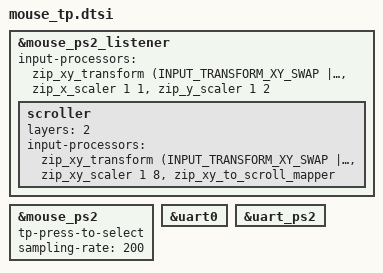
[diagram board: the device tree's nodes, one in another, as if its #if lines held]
#ifdef HAS_MOUSE_TP
  #include <dt-bindings/zmk/mouse.h>
  #include <dt-bindings/zmk/mouse_settings.h>
  #include <dt-bindings/zmk/input_transform.h>
  #include <input/processors.dtsi>
  #include <behaviors/mouse_keys.dtsi>
  #include <behaviors/mouse_setting.dtsi>

 /*
  * Key Behaviors to adjust settings
  */

  // They key codes below can be used to adjust the TP settings at runtime
  // without needing to recompile the firmware.
  //
  // The values will be logged and saved in the config on the controller flash
  // after 60s (CONFIG_ZMK_SETTINGS_SAVE_DEBOUNCE).
  //
  // On boot the settings will be restored again.
  //
  // If you prefer a more explicit way of configuration, you can also hardcode
  // these settings in `&mouse_ps2`.
  //
  // If you set these settings in `&mouse_ps2`, you will still be able to
  // adjust the values during runtime with these key codes, but after
  // restarting the board the values in `&mouse_ps2` will be restored and not
  // the ones stored in the flash using the key codes.


  // How sensitive the trackpoint is
  #define U_MSS_TP_S_I &mms MS_TP_SENSITIVITY_INCR
  #define U_MSS_TP_S_D &mms MS_TP_SENSITIVITY_DECR


  // The maximum speed the trackpoint will accelerate to
  #define U_MSS_TP_V6_I &mms MS_TP_VALUE6_INCR
  #define U_MSS_TP_V6_D &mms MS_TP_VALUE6_DECR


  // I am not quite sure tbh... default seems fine.
  #define U_MSS_TP_NI_I &mms MS_TP_NEG_INERTIA_INCR
  #define U_MSS_TP_NI_D &mms MS_TP_NEG_INERTIA_DECR


  // How hard you have to press to activate the "Press To Select" feature that
  // lets you tap or press on the trackpoint to click.
  //
  // Not all trackpoints support it and you have to enable
  // `tp-press-to-select;` in `&mouse_ps2` first.
  #define U_MSS_TP_PT_I &mms MS_TP_PTS_THRESHOLD_INCR
  #define U_MSS_TP_PT_D &mms MS_TP_PTS_THRESHOLD_DECR


  // If you mess up the settings, you can use this key code to clear the
  // settings from flash and re-set the default values on the TP.
  //
  // Make sure to wait at least CONFIG_ZMK_SETTINGS_SAVE_DEBOUNCE seconds (60
  // by default) before restarting the board to ensure the settings are
  // written to flash storage.
  #define U_MSS_RESET   &mms MS_RESET


  // If you prefer to set the settings in `&mouse_ps2`, you can use the key
  // codes above to find the settings you like the most and then press this
  // key code to output the settings to the log.
  //
  // Then you can add those values to `&mouse_ps2`
  #define U_MSS_LOG     &mms MS_LOG


  // Only apply these settings on the side that has the TP connected
  // (usually the right side)
  #ifdef MOUSE_PS2_DT_PRESENT

   /*
    * Input Listener Config
    *
    * The PS/2 driver registers itself as a plain Zephyr input device, so it
    * plugs into the upstream ZMK pointing device framework: the mainline
    * `zmk,input-listener` turns the device's events into HID mouse reports
    * and passes them through the input processors listed below.
    */

    &mouse_ps2_listener {

      status = "okay";

      // Adjust pointing device axes.
      // The transform processor swaps and inverts the axes so the trackpoint
      // matches the physical orientation of the TPS36. This adjusts the
      // values inside the zmk driver. Some trackpoints also allow you to
      // adjust it in their firmware. Check the driver options below for
      // more info.
      //
      // The two scalers run after the transform, so they scale the axes the
      // host actually sees. Each takes a (multiplier, divisor) pair and
      // keeps the fractional remainder across packets, so a ratio like 3/4
      // slows an axis down to 75% without quantising the motion.
      //
      // The trackpoint's sensor is not balanced across its two axes. The
      // 180 degree rotation above means the screen's vertical axis is driven
      // by the trackpoint's native X axis, which measures roughly twice the
      // movement of the native Y axis for the same physical push - so the
      // vertical axis is scaled down to match the horizontal one.
      //
      // Measured from the USB log: 11.55 movement units per packet for the
      // vertical strokes against 5.95 for the horizontal ones, and 2.55
      // against 1.06 for the cross axis leakage.
      //
      // The overall speed is not adjusted here - it is raised with the
      // trackpoint's own sensitivity setting (&mms), which affects both
      // axes at once.
      input-processors = <&zip_xy_transform (INPUT_TRANSFORM_XY_SWAP | INPUT_TRANSFORM_X_INVERT | INPUT_TRANSFORM_Y_INVERT)>,
                         <&zip_x_scaler 1 1>,
                         <&zip_y_scaler 1 2>;

      // On the function layer the trackpoint turns into a scroll wheel
      // instead of a pointer.
      //
      // An override that matches the active layer replaces the base
      // processors, so the chain is repeated here.
      //
      // The transform processor applies the axis swap first and the
      // inversion afterwards, so the invert flags end up on the opposite
      // axis of the one they are named after:
      //
      //   trackpoint native X -> REL_Y -> WHEEL  (vertical scroll)
      //   trackpoint native Y -> REL_X -> HWHEEL (horizontal scroll)
      //
      // The host leaves the vertical wheel alone but reverses the
      // horizontal one, so only the horizontal axis needs the inversion:
      // X_INVERT applies to the events that end up as REL_X, which are the
      // ones that become HWHEEL.
      //
      // The scaler divides the movement down to a sensible number of wheel
      // detents per packet.
      scroller {
          layers = <2>; // FUNC

          input-processors = <&zip_xy_transform (INPUT_TRANSFORM_XY_SWAP | INPUT_TRANSFORM_X_INVERT)>,
                             <&zip_xy_scaler 1 8>,
                             <&zip_xy_to_scroll_mapper>;
      };
    };


   /*
    * Mouse Driver Settings
    */

    &mouse_ps2 {

      // How sensitive the TP is (Default: 128)
      //
      // Left unset on purpose: the driver only applies a value that is
      // defined here, and when it is defined it also refuses to restore the
      // value stored in the flash. Leaving it unset means the &mms key
      // behaviors can adjust it at runtime and the value survives a reboot.
      // tp-sensitivity = <128>;


      // The maximum mouse movement speed the TP will accelarate to
      // (Default: 97)
      // tp-val6-upper-speed = <97>;


      // Negative Inertia (Default: 6)
      // Makes the TP feel more responsive and "overshoot" less.
      // tp-neg-inertia = <6>;


      // Enable clicking by tapping on the TP.
      // Not all TPs support this.
      tp-press-to-select;
      // tp-press-to-select-threshold = <10>;


      // Adjust axis settings on the TP
      // Works only on some trackpoints, but may be properly considered by the
      // trackpoint's acceleration features (which may or may not have an
      // impact).
      //
      // Alternatively consider achieving the same effect using the
      //  `input-listener` settings below.
      // tp-xy-swap;
      // tp-x-invert;
      // tp-y-invert;


      // Set sampling rate
      //
      // The frequency at which the mouse samples and sends data (in hz).
      // The default rate is 100. You can try lowering it if you experience
      // connection errors.
      //
      // 200 halves the input latency (5 ms instead of 10 ms per packet) at
      // the cost of a higher error rate and a higher mouse report rate,
      // which the BLE connection interval may not be able to carry.
      //
      // These values are allowed: 10,20,40,60,80,100,200
      sampling-rate = <200>;


      // Disables clicking.
      // Useful when using the PS2 GPIO driver that is prone to
      // erros in transmissions to reduce accidental clicks.
      // disable-clicking;


      // Enable scroll wheel
      // For mouse devices supporting the Intellimouse extension. Not relevant
      // for trackpoints
      // scroll-mode;

    };

    // Enable PS/2 Mouse Devices
    // In `your_keyboard_right.overlay` all devices have `status = "disabled"`.
    // So,they are never compiled into the firmware.
    //
    // Here we enable them, but we do it within the #ifdef HAS_MOUSE_TP code
    // block, which prevents compilation and potential build errors when we
    // undefine HAS_MOUSE_TP in corne_tp.keymap
    &mouse_ps2  {
      status = "okay";
    };

    #ifdef MOUSE_PS2_DRIVER_UART

      &uart0 {
        status = "okay";
      };

      &uart_ps2 {
        status="okay";
      };

    #else

      &gpio_ps2  {
        status = "okay";
      };

    #endif  // MOUSE_PS2_DRIVER_UART
  #endif  // MOUSE_PS2_DT_PRESENT
#endif  // HAS_MOUSE_TP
